# io8052 register map
Registers from a debugger description file.
Registers are 8-bit, access not given, reset 0x0 unless marked. A register's access mark holds for its fields unless they carry their own. Addresses are absolute; registers are grouped by the start of their names; lines under a group give offsets from that group; [hi:lo] are bit positions; {n}, {i} and the like mark numbered series; 'fields as' and 'values as' point back to an identical list; <NAME> marks a mode.

## Further device data
interrupts=NMI 0x00 1; extern0 0x03 2 IE.EX0 TCON.IE0; IE0_int 0x03 2 IE.EX0 TCON.IE0; timer0 0x0B 2 IE.ET0 TCON.TF0; TF0_int 0x0B 2 IE.ET0 TCON.TF0; extern1 0x13 2 IE.EX1 TCON.IE1; IE1_int 0x13 2 IE.EX1 TCON.IE1; timer1 0x1B 2 IE.ET1 TCON.TF1; TF1_int 0x1B 2 IE.ET1 TCON.TF1; sio_ti 0x23 2 IE.ES SCON.TI; sio_ri 0x23 2 IE.ES SCON.RI; TI_int 0x23 2 IE.ES SCON.TI; RI_int 0x23 2 IE.ES SCON.RI

## SFR
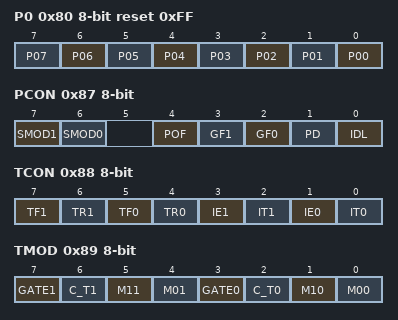
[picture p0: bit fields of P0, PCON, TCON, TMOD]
0x80 P0 reset 0xFF — Port 0
  [n] P{n:02} (n=0..7)
0x82 DPL — Data Pointer Low byte, LSB of DPTR
0x83 DPH — Data Pointer High byte, MSB of DPTR
0x87 PCON — Power Control
  [7] SMOD1, [6] SMOD0, [4] POF, [3] GF1, [2] GF0, [1] PD, [0] IDL
0x88 TCON — Timer Control
  [7] TF1, [6] TR1, [5] TF0, [4] TR0, [3] IE1, [2] IT1, [1] IE0, [0] IT0
0x89 TMOD — Timer Mode
  [7] GATE1, [6] C_T1, [5] M11, [4] M01, [3] GATE0, [2] C_T0, [1] M10, [0] M00
0x8A TL0 — Timer0 Low
0x8B TL1 — Timer1 Low
0x8C TH0 — Timer0 High
0x8D TH1 — Timer1 High
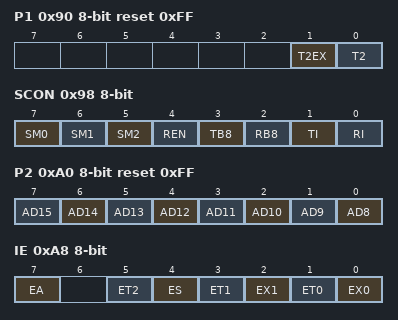
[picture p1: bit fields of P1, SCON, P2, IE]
0x90 P1 reset 0xFF — Port 1
  [1] T2EX, [0] T2
0x98 SCON — Serial Control
  [7] SM0, [6] SM1, [5] SM2, [4] REN, [3] TB8, [2] RB8, [1] TI, [0] RI
0x99 SBUF — Serial Data Buffer
0xA0 P2 reset 0xFF — Port 2
  [n-8] AD{n} (n=8..15)
0xA8 IE — Interrupt Enable
  [7] EA, [5] ET2, [4] ES, [3] ET1, [2] EX1, [1] ET0, [0] EX0
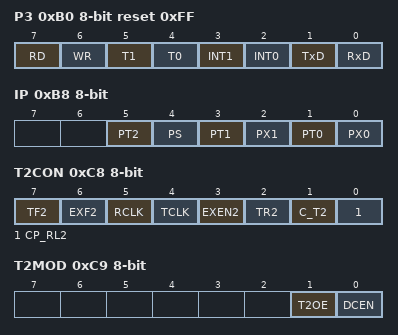
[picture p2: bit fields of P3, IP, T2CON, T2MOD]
0xB0 P3 reset 0xFF — Port 3
  [7] RD, [6] WR, [5] T1, [4] T0, [3] INT1, [2] INT0, [1] TxD, [0] RxD
0xB8 IP — Interrupt Priority
  [5] PT2, [4] PS, [3] PT1, [2] PX1, [1] PT0, [0] PX0
0xC8 T2CON — Timer 2 Control
  [7] TF2, [6] EXF2, [5] RCLK, [4] TCLK, [3] EXEN2, [2] TR2, [1] C_T2, [0] CP_RL2
0xC9 T2MOD — Timer 2 Mode Control
  [1] T2OE, [0] DCEN
0xCA RCAP2L — Timer2 Capture Low
0xCB RCAP2H — Timer2 Capture High
0xCC TL2 — Timer2 Low
0xCD TH2 — Timer2 High
